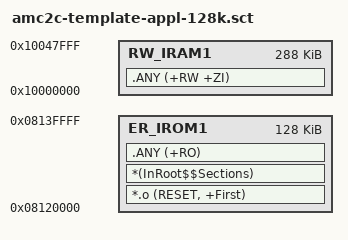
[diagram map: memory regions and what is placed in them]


LR_IROM1 0x08120000 0x20000  {    ; load region size_region
  ER_IROM1 0x08120000 0x20000  {  ; load address = execution address
   *.o (RESET, +First)
   *(InRoot$$Sections)
   .ANY (+RO)
  }
  RW_IRAM1 0x10000000 0x00048000{  ; RW data
   .ANY (+RW +ZI)
  }
}
